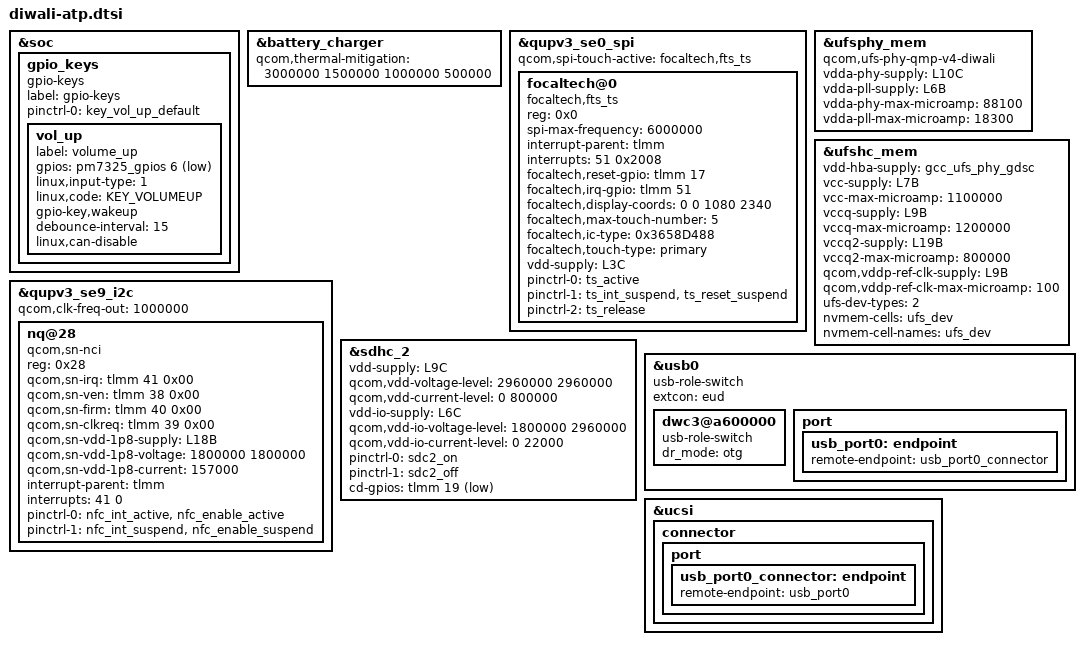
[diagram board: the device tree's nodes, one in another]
#include <dt-bindings/gpio/gpio.h>
#include <dt-bindings/input/input.h>

#include "diwali-pm7250b.dtsi"
#include "diwali-pmic-overlay.dtsi"
#include "diwali-thermal-overlay.dtsi"

&soc {
	gpio_keys {
		compatible = "gpio-keys";
		label = "gpio-keys";

		pinctrl-names = "default";
		pinctrl-0 = <&key_vol_up_default>;

		vol_up {
			label = "volume_up";
			gpios = <&pm7325_gpios 6 GPIO_ACTIVE_LOW>;
			linux,input-type = <1>;
			linux,code = <KEY_VOLUMEUP>;
			gpio-key,wakeup;
			debounce-interval = <15>;
			linux,can-disable;
		};
	};
};

&battery_charger {
	qcom,thermal-mitigation = <3000000 1500000 1000000 500000>;
};

&qupv3_se0_spi {
	status = "ok";

	#address-cells = <1>;
	#size-cells = <0>;
	qcom,spi-touch-active = "focaltech,fts_ts";

	focaltech@0 {
		compatible = "focaltech,fts_ts";
		reg = <0x0>;
		spi-max-frequency = <6000000>;
		interrupt-parent = <&tlmm>;
		interrupts = <51 0x2008>;
		focaltech,reset-gpio = <&tlmm 17 0x00>;
		focaltech,irq-gpio = <&tlmm 51 0x2008>;
		focaltech,display-coords = <0 0 1080 2340>;
		focaltech,max-touch-number = <5>;
		focaltech,ic-type = <0x3658D488>;
		focaltech,touch-type = "primary";

		vdd-supply = <&L3C>;

		pinctrl-names = "pmx_ts_active", "pmx_ts_suspend", "pmx_ts_release";
		pinctrl-0 = <&ts_active>;
		pinctrl-1 = <&ts_int_suspend &ts_reset_suspend>;
		pinctrl-2 = <&ts_release>;
	};
};

&qupv3_se9_i2c {
	status = "ok";
	qcom,clk-freq-out = <1000000>;
	#address-cells = <1>;
	#size-cells = <0>;
	nq@28 {
		compatible = "qcom,sn-nci";
		reg = <0x28>;
		qcom,sn-irq = <&tlmm 41 0x00>;
		qcom,sn-ven = <&tlmm 38 0x00>;
		qcom,sn-firm = <&tlmm 40 0x00>;
		qcom,sn-clkreq = <&tlmm 39 0x00>;
		qcom,sn-vdd-1p8-supply = <&L18B>;
		qcom,sn-vdd-1p8-voltage = <1800000 1800000>;
		qcom,sn-vdd-1p8-current = <157000>;
		interrupt-parent = <&tlmm>;
		interrupts = <41 0>;
		interrupt-names = "nfc_irq";
		pinctrl-names = "nfc_active", "nfc_suspend";
		pinctrl-0 = <&nfc_int_active &nfc_enable_active>;
		pinctrl-1 = <&nfc_int_suspend &nfc_enable_suspend>;
	};
};

&sdhc_2 {
	status = "ok";
	vdd-supply = <&L9C>;
	qcom,vdd-voltage-level = <2960000 2960000>;
	qcom,vdd-current-level = <0 800000>;

	vdd-io-supply = <&L6C>;
	qcom,vdd-io-voltage-level = <1800000 2960000>;
	qcom,vdd-io-current-level = <0 22000>;

	pinctrl-names = "default", "sleep";
	pinctrl-0 = <&sdc2_on>;
	pinctrl-1 = <&sdc2_off>;

	cd-gpios = <&tlmm 19 GPIO_ACTIVE_LOW>;
};

&ufsphy_mem {
	compatible = "qcom,ufs-phy-qmp-v4-diwali";

	vdda-phy-supply = <&L10C>;
	vdda-pll-supply = <&L6B>;
	vdda-phy-max-microamp = <88100>;
	vdda-pll-max-microamp = <18300>;

	status = "ok";
};

&ufshc_mem {
	vdd-hba-supply = <&gcc_ufs_phy_gdsc>;

	vcc-supply = <&L7B>;
	vcc-max-microamp = <1100000>;

	vccq-supply = <&L9B>;
	vccq-max-microamp = <1200000>;

	vccq2-supply = <&L19B>;
	vccq2-max-microamp = <800000>;

	qcom,vddp-ref-clk-supply = <&L9B>;
	qcom,vddp-ref-clk-max-microamp = <100>;

	/*
	 * ufs-dev-types and nvmem entries are for ufs device
	 * identification using nvmem interface. Use number of
	 * ufs devices supported for ufs-dev-types, and nvmem handle
	 * added by pmic for sdam register.
	 */
	ufs-dev-types = <2>;
	nvmem-cells = <&ufs_dev>;
	nvmem-cell-names = "ufs_dev";

	status = "ok";
};

&usb0 {
	usb-role-switch;
	extcon = <&eud>;

	dwc3@a600000 {
		usb-role-switch;
		dr_mode = "otg";
	};

	port {
		usb_port0: endpoint {
			remote-endpoint = <&usb_port0_connector>;
		};
	};
};

&ucsi {
	connector {
		port {
			usb_port0_connector: endpoint {
				remote-endpoint = <&usb_port0>;
			};
		};
	};
};
